# TM4C1231H6PM register map
Vendor: Texas Instruments; File version: 11073
CPU: CM4 r1p2, little endian, no MPU, no FPU, 0x3 interrupt priority bits, 0x0 interrupts
Registers are 32-bit, read-write, no defined reset value unless marked. A register's access mark holds for its fields unless they carry their own. Offsets are from the block's base; [hi:lo] are bit positions; {n}, {i} and the like mark numbered series.

## SSI0 — Register map for SSI0 peripheral
Base 0x40008000; register names take the prefix SSI0
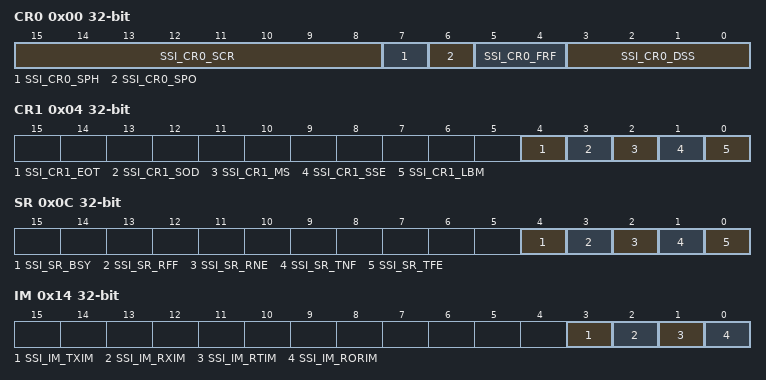
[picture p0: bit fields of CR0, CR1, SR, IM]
0x00 CR0 — SSI Control 0
  [15:8] SSI_CR0_SCR — SSI Serial Clock Rate
  [7] SSI_CR0_SPH — SSI Serial Clock Phase
  [6] SSI_CR0_SPO — SSI Serial Clock Polarity
  [5:4] SSI_CR0_FRF — SSI Frame Format Select
    0=SSI_CR0_FRF_MOTO (Freescale SPI Frame Format); 1=SSI_CR0_FRF_TI (Texas Instruments Synchronous Serial Frame Format); 2=SSI_CR0_FRF_NMW (MICROWIRE Frame Format)
  [3:0] SSI_CR0_DSS — SSI Data Size Select
    {v}={v+1}-bit data (v=3..15)
0x04 CR1 — SSI Control 1
  [4] SSI_CR1_EOT — End of Transmission
  [3] SSI_CR1_SOD — SSI Slave Mode Output Disable
  [2] SSI_CR1_MS — SSI Master/Slave Select
  [1] SSI_CR1_SSE — SSI Synchronous Serial Port Enable
  [0] SSI_CR1_LBM — SSI Loopback Mode
0x08 DR — SSI Data
  [15:0] SSI_DR_DATA — SSI Receive/Transmit Data
0x0C SR — SSI Status
  [4] SSI_SR_BSY — SSI Busy Bit
  [3] SSI_SR_RFF — SSI Receive FIFO Full
  [2] SSI_SR_RNE — SSI Receive FIFO Not Empty
  [1] SSI_SR_TNF — SSI Transmit FIFO Not Full
  [0] SSI_SR_TFE — SSI Transmit FIFO Empty
0x10 CPSR — SSI Clock Prescale
  [7:0] SSI_CPSR_CPSDVSR — SSI Clock Prescale Divisor
0x14 IM — SSI Interrupt Mask
  [3] SSI_IM_TXIM — SSI Transmit FIFO Interrupt Mask
  [2] SSI_IM_RXIM — SSI Receive FIFO Interrupt Mask
  [1] SSI_IM_RTIM — SSI Receive Time-Out Interrupt Mask
  [0] SSI_IM_RORIM — SSI Receive Overrun Interrupt Mask
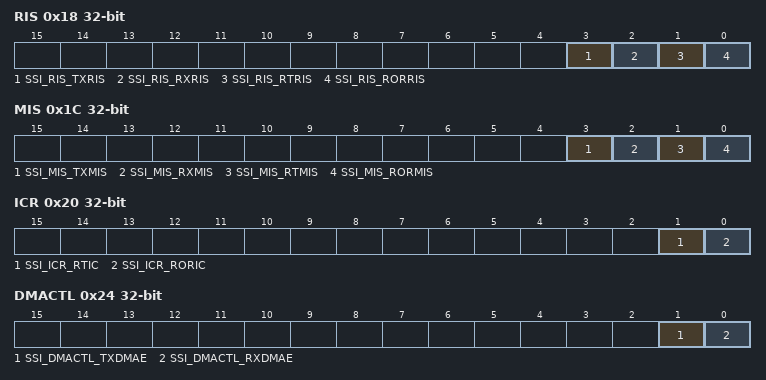
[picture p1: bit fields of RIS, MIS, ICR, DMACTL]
0x18 RIS — SSI Raw Interrupt Status
  [3] SSI_RIS_TXRIS — SSI Transmit FIFO Raw Interrupt Status
  [2] SSI_RIS_RXRIS — SSI Receive FIFO Raw Interrupt Status
  [1] SSI_RIS_RTRIS — SSI Receive Time-Out Raw Interrupt Status
  [0] SSI_RIS_RORRIS — SSI Receive Overrun Raw Interrupt Status
0x1C MIS — SSI Masked Interrupt Status
  [3] SSI_MIS_TXMIS — SSI Transmit FIFO Masked Interrupt Status
  [2] SSI_MIS_RXMIS — SSI Receive FIFO Masked Interrupt Status
  [1] SSI_MIS_RTMIS — SSI Receive Time-Out Masked Interrupt Status
  [0] SSI_MIS_RORMIS — SSI Receive Overrun Masked Interrupt Status
0x20 ICR wo — SSI Interrupt Clear
  [1] SSI_ICR_RTIC — SSI Receive Time-Out Interrupt Clear
  [0] SSI_ICR_RORIC — SSI Receive Overrun Interrupt Clear
0x24 DMACTL — SSI DMA Control
  [1] SSI_DMACTL_TXDMAE — Transmit DMA Enable
  [0] SSI_DMACTL_RXDMAE — Receive DMA Enable
0xFC8 CC — SSI Clock Configuration
  [3:0] SSI_CC_CS — SSI Baud Clock Source
    0=SSI_CC_CS_SYSPLL (Either the system clock (if the PLL bypass is in effect) or the PLL output (default)); 5=SSI_CC_CS_PIOSC (PIOSC)

## SSI1 — Register map for SSI0 peripheral
Base 0x40009000; register names take the prefix SSI1
Registers as SSI0.

## SSI2 — Register map for SSI0 peripheral
Base 0x4000A000; register names take the prefix SSI2
Registers as SSI0.

## SSI3 — Register map for SSI0 peripheral
Base 0x4000B000; register names take the prefix SSI3
Registers as SSI0.

## COMP — Register map for COMP peripheral
Base 0x4003C000; register names take the prefix COMP
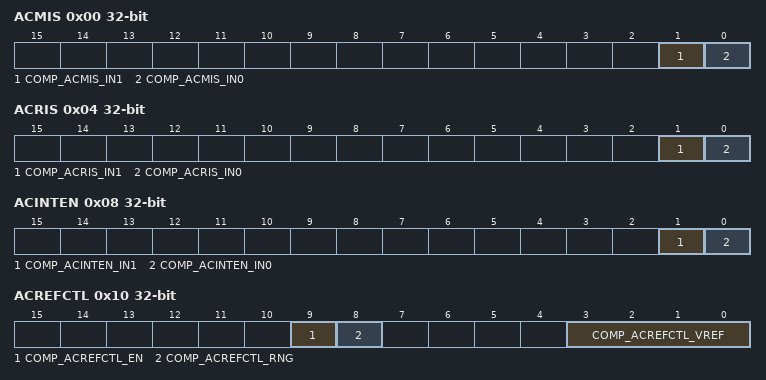
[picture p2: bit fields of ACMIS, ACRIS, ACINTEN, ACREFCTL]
0x00 ACMIS — Analog Comparator Masked Interrupt Status
  [1] COMP_ACMIS_IN1 — Comparator 1 Masked Interrupt Status
  [0] COMP_ACMIS_IN0 — Comparator 0 Masked Interrupt Status
0x04 ACRIS — Analog Comparator Raw Interrupt Status
  [1] COMP_ACRIS_IN1 — Comparator 1 Interrupt Status
  [0] COMP_ACRIS_IN0 — Comparator 0 Interrupt Status
0x08 ACINTEN — Analog Comparator Interrupt Enable
  [1] COMP_ACINTEN_IN1 — Comparator 1 Interrupt Enable
  [0] COMP_ACINTEN_IN0 — Comparator 0 Interrupt Enable
0x10 ACREFCTL — Analog Comparator Reference Voltage Control
  [9] COMP_ACREFCTL_EN — Resistor Ladder Enable
  [8] COMP_ACREFCTL_RNG — Resistor Ladder Range
  [3:0] COMP_ACREFCTL_VREF — Resistor Ladder Voltage Ref
0x20 ACSTAT0 — Analog Comparator Status 0
  [1] COMP_ACSTAT0_OVAL — Comparator Output Value
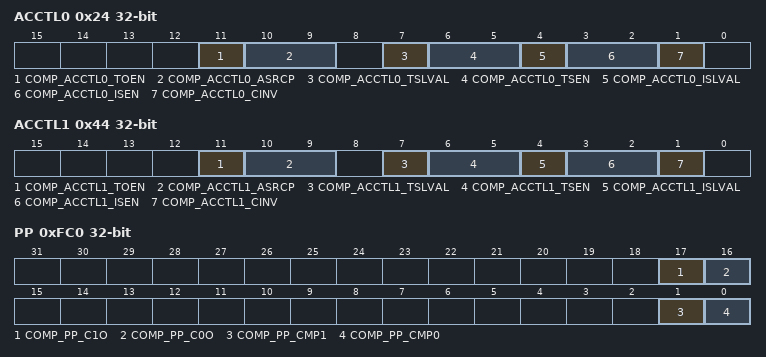
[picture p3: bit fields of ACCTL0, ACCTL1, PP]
0x24 ACCTL0 — Analog Comparator Control 0
  [11] COMP_ACCTL0_TOEN — Trigger Output Enable
  [10:9] COMP_ACCTL0_ASRCP — Analog Source Positive
    0=COMP_ACCTL0_ASRCP_PIN (Pin value of Cn+); 1=COMP_ACCTL0_ASRCP_PIN0 (Pin value of C0+); 2=COMP_ACCTL0_ASRCP_REF (Internal voltage reference)
  [7] COMP_ACCTL0_TSLVAL — Trigger Sense Level Value
  [6:5] COMP_ACCTL0_TSEN — Trigger Sense
    0=COMP_ACCTL0_TSEN_LEVEL (Level sense, see TSLVAL); 1=COMP_ACCTL0_TSEN_FALL (Falling edge); 2=COMP_ACCTL0_TSEN_RISE (Rising edge); 3=COMP_ACCTL0_TSEN_BOTH (Either edge)
  [4] COMP_ACCTL0_ISLVAL — Interrupt Sense Level Value
  [3:2] COMP_ACCTL0_ISEN — Interrupt Sense
    0=COMP_ACCTL0_ISEN_LEVEL (Level sense, see ISLVAL); 1=COMP_ACCTL0_ISEN_FALL (Falling edge); 2=COMP_ACCTL0_ISEN_RISE (Rising edge); 3=COMP_ACCTL0_ISEN_BOTH (Either edge)
  [1] COMP_ACCTL0_CINV — Comparator Output Invert
0x40 ACSTAT1 — Analog Comparator Status 1
  [1] COMP_ACSTAT1_OVAL — Comparator Output Value
0x44 ACCTL1 — Analog Comparator Control 1
  [11] COMP_ACCTL1_TOEN — Trigger Output Enable
  [10:9] COMP_ACCTL1_ASRCP — Analog Source Positive
    0=COMP_ACCTL1_ASRCP_PIN (Pin value of Cn+); 1=COMP_ACCTL1_ASRCP_PIN0 (Pin value of C0+); 2=COMP_ACCTL1_ASRCP_REF (Internal voltage reference (VIREF))
  [7] COMP_ACCTL1_TSLVAL — Trigger Sense Level Value
  [6:5] COMP_ACCTL1_TSEN — Trigger Sense
    0=COMP_ACCTL1_TSEN_LEVEL (Level sense, see TSLVAL); 1=COMP_ACCTL1_TSEN_FALL (Falling edge); 2=COMP_ACCTL1_TSEN_RISE (Rising edge); 3=COMP_ACCTL1_TSEN_BOTH (Either edge)
  [4] COMP_ACCTL1_ISLVAL — Interrupt Sense Level Value
  [3:2] COMP_ACCTL1_ISEN — Interrupt Sense
    0=COMP_ACCTL1_ISEN_LEVEL (Level sense, see ISLVAL); 1=COMP_ACCTL1_ISEN_FALL (Falling edge); 2=COMP_ACCTL1_ISEN_RISE (Rising edge); 3=COMP_ACCTL1_ISEN_BOTH (Either edge)
  [1] COMP_ACCTL1_CINV — Comparator Output Invert
0xFC0 PP — Analog Comparator Peripheral Properties
  [17] COMP_PP_C1O — Comparator Output 1 Present
  [16] COMP_PP_C0O — Comparator Output 0 Present
  [1] COMP_PP_CMP1 — Comparator 1 Present
  [0] COMP_PP_CMP0 — Comparator 0 Present
